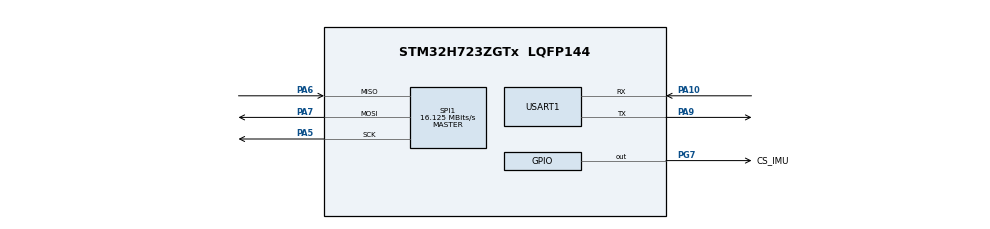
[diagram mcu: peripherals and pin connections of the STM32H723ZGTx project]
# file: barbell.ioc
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CORTEX_M7.default_mode_Activation=1
Mcu.Family=STM32H7
Mcu.Name=STM32H723ZGTx
Mcu.Package=LQFP144
NVIC.PriorityGroup=NVIC_PRIORITYGROUP_4
PA10.Mode=Asynchronous
PA10.Signal=USART1_RX
PA13(JTMS/SWDIO).Mode=Serial_Wire
PA13(JTMS/SWDIO).Signal=DEBUG_JTMS-SWDIO
PA14(JTCK/SWCLK).Mode=Serial_Wire
PA14(JTCK/SWCLK).Signal=DEBUG_JTCK-SWCLK
PA5.Mode=Full_Duplex_Master
PA5.Signal=SPI1_SCK
PA6.Mode=Full_Duplex_Master
PA6.Signal=SPI1_MISO
PA7.Mode=Full_Duplex_Master
PA7.Signal=SPI1_MOSI
PA9.Mode=Asynchronous
PA9.Signal=USART1_TX
PG7.GPIO_Label=CS_IMU
PG7.Signal=GPIO_Output
ProjectManager.HeapSize=0x200
ProjectManager.StackSize=0x400
ProjectManager.TargetToolchain=Makefile
RCC.ADCFreq_Value=129000000
RCC.APB1Freq_Value=64000000
RCC.APB2Freq_Value=64000000
RCC.APB3Freq_Value=64000000
RCC.APB4Freq_Value=64000000
RCC.CortexFreq_Value=64000000
RCC.HCLKFreq_Value=64000000
RCC.SYSCLKFreq_VALUE=64000000
RCC.USBFreq_Value=129000000
SPI1.BaudRatePrescaler=SPI_BAUDRATEPRESCALER_8
SPI1.CLKPhase=SPI_PHASE_2EDGE
SPI1.CLKPolarity=SPI_POLARITY_HIGH
SPI1.CalculateBaudRate=16.125 MBits/s
SPI1.DataSize=SPI_DATASIZE_8BIT
SPI1.Direction=SPI_DIRECTION_2LINES
SPI1.Mode=SPI_MODE_MASTER
SPI1.VirtualType=VM_MASTER
USART1.VirtualMode-Asynchronous=VM_ASYNC
VP_MEMORYMAP_VS_MEMORYMAP.Mode=CurAppReg
VP_TIM1_VS_ClockSourceINT.Mode=Internal
board=custom

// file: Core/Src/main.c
/* USER CODE BEGIN Header */
/**
  ******************************************************************************
  * @file           : main.c
  * @brief          : Main program body
  ******************************************************************************
  * @attention
  *
  * Copyright (c) 2026 STMicroelectronics.
  * All rights reserved.
  *
  * This software is licensed under terms that can be found in the LICENSE file
  * in the root directory of this software component.
  * If no LICENSE file comes with this software, it is provided AS-IS.
  *
  ******************************************************************************
  */
/* USER CODE END Header */
#include "main.h"

/* USER CODE BEGIN Includes */
#include "spi_imu.h"
/* USER CODE END Includes */

SPI_HandleTypeDef hspi1;

TIM_HandleTypeDef htim1;

UART_HandleTypeDef huart1;

void SystemClock_Config(void);
static void MPU_Config(void);
static void MX_GPIO_Init(void);
static void MX_USART1_UART_Init(void);
static void MX_SPI1_Init(void);
static void MX_TIM1_Init(void);

/* USER CODE BEGIN 0 */
int __io_putchar(int ch)
{
  HAL_UART_Transmit(&huart1, (uint8_t *)&ch, 1, HAL_MAX_DELAY);
  return ch;
}

spi_device_t spi_imu_dev = {
  &hspi1,
  CS_IMU_GPIO_Port,
  CS_IMU_Pin
};
/* USER CODE END 0 */

int main(void)
{

  /* MPU Configuration--------------------------------------------------------*/
  MPU_Config();

  /* MCU Configuration--------------------------------------------------------*/

  /* Reset of all peripherals, Initializes the Flash interface and the Systick. */
  HAL_Init();

  /* Configure the system clock */
  SystemClock_Config();

  /* Initialize all configured peripherals */
  MX_GPIO_Init();
  MX_USART1_UART_Init();
  MX_SPI1_Init();
  MX_TIM1_Init();

  /* Infinite loop */
  while (1)
  {

    /* USER CODE BEGIN 3 */
    imu_who_am_i_test(&spi_imu_dev);
    HAL_Delay(500);
  }
  /* USER CODE END 3 */
}

void SystemClock_Config(void)
{
  RCC_OscInitTypeDef RCC_OscInitStruct = {0};
  RCC_ClkInitTypeDef RCC_ClkInitStruct = {0};

  /** Supply configuration update enable
  */
  HAL_PWREx_ConfigSupply(PWR_LDO_SUPPLY);

  /** Configure the main internal regulator output voltage
  */
  __HAL_PWR_VOLTAGESCALING_CONFIG(PWR_REGULATOR_VOLTAGE_SCALE3);

  while(!__HAL_PWR_GET_FLAG(PWR_FLAG_VOSRDY)) {}

  /** Initializes the RCC Oscillators according to the specified parameters
  * in the RCC_OscInitTypeDef structure.
  */
  RCC_OscInitStruct.OscillatorType = RCC_OSCILLATORTYPE_HSI;
  RCC_OscInitStruct.HSIState = RCC_HSI_DIV1;
  RCC_OscInitStruct.HSICalibrationValue = 64;
  RCC_OscInitStruct.PLL.PLLState = RCC_PLL_ON;
  RCC_OscInitStruct.PLL.PLLSource = RCC_PLLSOURCE_HSI;
  RCC_OscInitStruct.PLL.PLLM = 32;
  RCC_OscInitStruct.PLL.PLLN = 129;
  RCC_OscInitStruct.PLL.PLLP = 2;
  RCC_OscInitStruct.PLL.PLLQ = 2;
  RCC_OscInitStruct.PLL.PLLR = 2;
  RCC_OscInitStruct.PLL.PLLRGE = RCC_PLL1VCIRANGE_1;
  RCC_OscInitStruct.PLL.PLLVCOSEL = RCC_PLL1VCOWIDE;
  RCC_OscInitStruct.PLL.PLLFRACN = 0;
  if (HAL_RCC_OscConfig(&RCC_OscInitStruct) != HAL_OK)
  {
    Error_Handler();
  }

  /** Initializes the CPU, AHB and APB buses clocks
  */
  RCC_ClkInitStruct.ClockType = RCC_CLOCKTYPE_HCLK|RCC_CLOCKTYPE_SYSCLK
                              |RCC_CLOCKTYPE_PCLK1|RCC_CLOCKTYPE_PCLK2
                              |RCC_CLOCKTYPE_D3PCLK1|RCC_CLOCKTYPE_D1PCLK1;
  RCC_ClkInitStruct.SYSCLKSource = RCC_SYSCLKSOURCE_HSI;
  RCC_ClkInitStruct.SYSCLKDivider = RCC_SYSCLK_DIV1;
  RCC_ClkInitStruct.AHBCLKDivider = RCC_HCLK_DIV1;
  RCC_ClkInitStruct.APB3CLKDivider = RCC_APB3_DIV1;
  RCC_ClkInitStruct.APB1CLKDivider = RCC_APB1_DIV1;
  RCC_ClkInitStruct.APB2CLKDivider = RCC_APB2_DIV1;
  RCC_ClkInitStruct.APB4CLKDivider = RCC_APB4_DIV1;

  if (HAL_RCC_ClockConfig(&RCC_ClkInitStruct, FLASH_LATENCY_1) != HAL_OK)
  {
    Error_Handler();
  }
}

static void MX_SPI1_Init(void)
{

  /* SPI1 parameter configuration*/
  hspi1.Instance = SPI1;
  hspi1.Init.Mode = SPI_MODE_MASTER;
  hspi1.Init.Direction = SPI_DIRECTION_2LINES;
  hspi1.Init.DataSize = SPI_DATASIZE_8BIT;
  hspi1.Init.CLKPolarity = SPI_POLARITY_HIGH;
  hspi1.Init.CLKPhase = SPI_PHASE_2EDGE;
  hspi1.Init.NSS = SPI_NSS_SOFT;
  hspi1.Init.BaudRatePrescaler = SPI_BAUDRATEPRESCALER_8;
  hspi1.Init.FirstBit = SPI_FIRSTBIT_MSB;
  hspi1.Init.TIMode = SPI_TIMODE_DISABLE;
  hspi1.Init.CRCCalculation = SPI_CRCCALCULATION_DISABLE;
  hspi1.Init.CRCPolynomial = 0x0;
  hspi1.Init.NSSPMode = SPI_NSS_PULSE_ENABLE;
  hspi1.Init.NSSPolarity = SPI_NSS_POLARITY_LOW;
  hspi1.Init.FifoThreshold = SPI_FIFO_THRESHOLD_01DATA;
  hspi1.Init.TxCRCInitializationPattern = SPI_CRC_INITIALIZATION_ALL_ZERO_PATTERN;
  hspi1.Init.RxCRCInitializationPattern = SPI_CRC_INITIALIZATION_ALL_ZERO_PATTERN;
  hspi1.Init.MasterSSIdleness = SPI_MASTER_SS_IDLENESS_00CYCLE;
  hspi1.Init.MasterInterDataIdleness = SPI_MASTER_INTERDATA_IDLENESS_00CYCLE;
  hspi1.Init.MasterReceiverAutoSusp = SPI_MASTER_RX_AUTOSUSP_DISABLE;
  hspi1.Init.MasterKeepIOState = SPI_MASTER_KEEP_IO_STATE_DISABLE;
  hspi1.Init.IOSwap = SPI_IO_SWAP_DISABLE;
  if (HAL_SPI_Init(&hspi1) != HAL_OK)
  {
    Error_Handler();
  }

}

static void MX_TIM1_Init(void)
{

  TIM_ClockConfigTypeDef sClockSourceConfig = {0};
  TIM_MasterConfigTypeDef sMasterConfig = {0};

  htim1.Instance = TIM1;
  htim1.Init.Prescaler = 0;
  htim1.Init.CounterMode = TIM_COUNTERMODE_UP;
  htim1.Init.Period = 65535;
  htim1.Init.ClockDivision = TIM_CLOCKDIVISION_DIV1;
  htim1.Init.RepetitionCounter = 0;
  htim1.Init.AutoReloadPreload = TIM_AUTORELOAD_PRELOAD_DISABLE;
  if (HAL_TIM_Base_Init(&htim1) != HAL_OK)
  {
    Error_Handler();
  }
  sClockSourceConfig.ClockSource = TIM_CLOCKSOURCE_INTERNAL;
  if (HAL_TIM_ConfigClockSource(&htim1, &sClockSourceConfig) != HAL_OK)
  {
    Error_Handler();
  }
  sMasterConfig.MasterOutputTrigger = TIM_TRGO_RESET;
  sMasterConfig.MasterOutputTrigger2 = TIM_TRGO2_RESET;
  sMasterConfig.MasterSlaveMode = TIM_MASTERSLAVEMODE_DISABLE;
  if (HAL_TIMEx_MasterConfigSynchronization(&htim1, &sMasterConfig) != HAL_OK)
  {
    Error_Handler();
  }

}

static void MX_USART1_UART_Init(void)
{

  huart1.Instance = USART1;
  huart1.Init.BaudRate = 115200;
  huart1.Init.WordLength = UART_WORDLENGTH_8B;
  huart1.Init.StopBits = UART_STOPBITS_1;
  huart1.Init.Parity = UART_PARITY_NONE;
  huart1.Init.Mode = UART_MODE_TX_RX;
  huart1.Init.HwFlowCtl = UART_HWCONTROL_NONE;
  huart1.Init.OverSampling = UART_OVERSAMPLING_16;
  huart1.Init.OneBitSampling = UART_ONE_BIT_SAMPLE_DISABLE;
  huart1.Init.ClockPrescaler = UART_PRESCALER_DIV1;
  huart1.AdvancedInit.AdvFeatureInit = UART_ADVFEATURE_NO_INIT;
  if (HAL_UART_Init(&huart1) != HAL_OK)
  {
    Error_Handler();
  }
  if (HAL_UARTEx_SetTxFifoThreshold(&huart1, UART_TXFIFO_THRESHOLD_1_8) != HAL_OK)
  {
    Error_Handler();
  }
  if (HAL_UARTEx_SetRxFifoThreshold(&huart1, UART_RXFIFO_THRESHOLD_1_8) != HAL_OK)
  {
    Error_Handler();
  }
  if (HAL_UARTEx_DisableFifoMode(&huart1) != HAL_OK)
  {
    Error_Handler();
  }

}

static void MX_GPIO_Init(void)
{
  GPIO_InitTypeDef GPIO_InitStruct = {0};

  /* GPIO Ports Clock Enable */
  __HAL_RCC_GPIOA_CLK_ENABLE();
  __HAL_RCC_GPIOG_CLK_ENABLE();

  /*Configure GPIO pin Output Level */
  HAL_GPIO_WritePin(CS_IMU_GPIO_Port, CS_IMU_Pin, GPIO_PIN_RESET);

  /*Configure GPIO pin : CS_IMU_Pin */
  GPIO_InitStruct.Pin = CS_IMU_Pin;
  GPIO_InitStruct.Mode = GPIO_MODE_OUTPUT_PP;
  GPIO_InitStruct.Pull = GPIO_NOPULL;
  GPIO_InitStruct.Speed = GPIO_SPEED_FREQ_LOW;
  HAL_GPIO_Init(CS_IMU_GPIO_Port, &GPIO_InitStruct);

}

 /* MPU Configuration */

void MPU_Config(void)
{
  MPU_Region_InitTypeDef MPU_InitStruct = {0};

  /* Disables the MPU */
  HAL_MPU_Disable();

  /** Initializes and configures the Region and the memory to be protected
  */
  MPU_InitStruct.Enable = MPU_REGION_ENABLE;
  MPU_InitStruct.Number = MPU_REGION_NUMBER0;
  MPU_InitStruct.BaseAddress = 0x0;
  MPU_InitStruct.Size = MPU_REGION_SIZE_4GB;
  MPU_InitStruct.SubRegionDisable = 0x87;
  MPU_InitStruct.TypeExtField = MPU_TEX_LEVEL0;
  MPU_InitStruct.AccessPermission = MPU_REGION_NO_ACCESS;
  MPU_InitStruct.DisableExec = MPU_INSTRUCTION_ACCESS_DISABLE;
  MPU_InitStruct.IsShareable = MPU_ACCESS_SHAREABLE;
  MPU_InitStruct.IsCacheable = MPU_ACCESS_NOT_CACHEABLE;
  MPU_InitStruct.IsBufferable = MPU_ACCESS_NOT_BUFFERABLE;

  HAL_MPU_ConfigRegion(&MPU_InitStruct);
  /* Enables the MPU */
  HAL_MPU_Enable(MPU_PRIVILEGED_DEFAULT);

}

void Error_Handler(void)
{
  __disable_irq();
  while (1)
  {
  }
}
